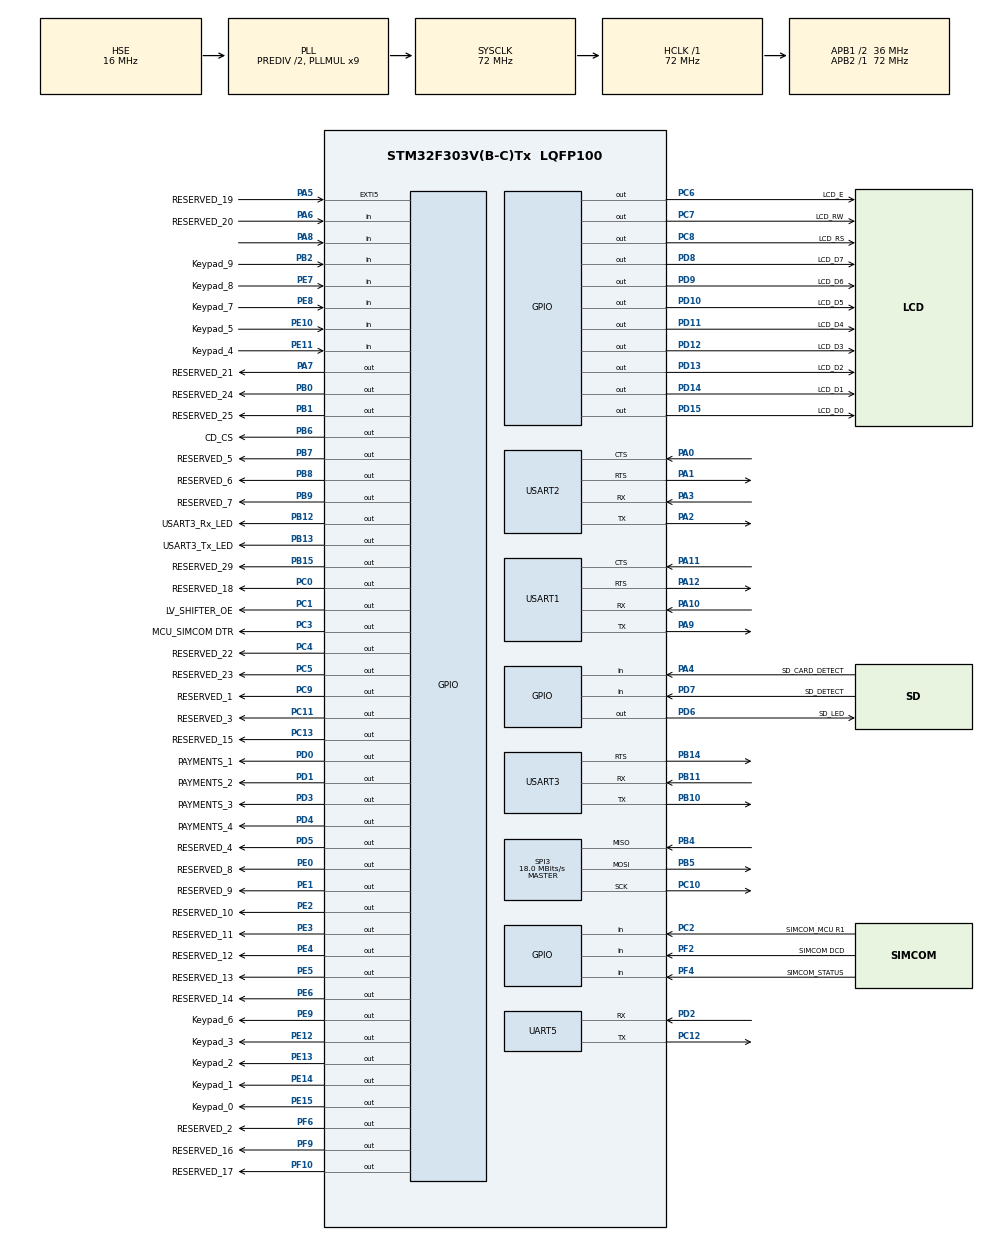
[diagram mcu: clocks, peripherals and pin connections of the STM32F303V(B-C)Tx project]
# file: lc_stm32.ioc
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FATFS._CODE_PAGE=1251
FREERTOS.Tasks01=defaultTask,0,128,StartDefaultTask,Default,NULL,Dynamic,NULL,NULL;keybScanTask,-3,128,KeybScanTask,Default,NULL,Dynamic,NULL,NULL
FREERTOS.configTOTAL_HEAP_SIZE=7000
FREERTOS.configUSE_TIMERS=1
Mcu.Family=STM32F3
Mcu.Name=STM32F303V(B-C)Tx
Mcu.Package=LQFP100
NVIC.PriorityGroup=NVIC_PRIORITYGROUP_4
NVIC.TIM1_BRK_TIM15_IRQn=true\:0\:0\:false\:false\:true\:false
NVIC.TimeBase=TIM1_BRK_TIM15_IRQn
NVIC.TimeBaseIP=TIM15
PA0.Mode=CTS_RTS
PA0.Signal=USART2_CTS
PA1.Mode=CTS_RTS
PA1.Signal=USART2_RTS
PA10.Mode=Asynchronous
PA10.Signal=USART1_RX
PA11.Mode=CTS_RTS
PA11.Signal=USART1_CTS
PA12.Mode=CTS_RTS
PA12.Signal=USART1_RTS
PA13.Mode=JTAG_4_pins
PA13.Signal=SYS_JTMS-SWDIO
PA14.Mode=JTAG_4_pins
PA14.Signal=SYS_JTCK-SWCLK
PA15.Mode=JTAG_4_pins
PA15.Signal=SYS_JTDI
PA2.Mode=Asynchronous
PA2.Signal=USART2_TX
PA3.Mode=Asynchronous
PA3.Signal=USART2_RX
PA4.GPIO_Label=SD_CARD_DETECT
PA4.Signal=GPIO_Input
PA5.GPIO_Label=RESERVED_19
PA5.GPIO_PuPd=GPIO_PULLDOWN
PA5.Signal=GPXTI5
PA6.GPIO_Label=RESERVED_20
PA6.GPIO_PuPd=GPIO_PULLDOWN
PA6.Signal=GPIO_Input
PA7.GPIO_Label=RESERVED_21
PA7.GPIO_PuPd=GPIO_PULLDOWN
PA7.Signal=GPIO_Output
PA8.Signal=GPIO_Input
PA9.Mode=Asynchronous
PA9.Signal=USART1_TX
PB0.GPIO_Label=RESERVED_24
PB0.GPIO_PuPd=GPIO_PULLDOWN
PB0.Signal=GPIO_Output
PB1.GPIO_Label=RESERVED_25
PB1.GPIO_PuPd=GPIO_PULLDOWN
PB1.Signal=GPIO_Output
PB10.Mode=Asynchronous
PB10.Signal=USART3_TX
PB11.Mode=Asynchronous
PB11.Signal=USART3_RX
PB12.GPIO_Label=USART3_Rx_LED
PB12.Signal=GPIO_Output
PB13.GPIO_Label=USART3_Tx_LED
PB13.Signal=GPIO_Output
PB14.Mode=RTS_Only
PB14.Signal=USART3_RTS
PB15.GPIO_Label=RESERVED_29
PB15.GPIO_PuPd=GPIO_PULLDOWN
PB15.Signal=GPIO_Output
PB2.GPIO_Label=Keypad_9
PB2.Signal=GPIO_Input
PB3.Mode=JTAG_4_pins
PB3.Signal=SYS_JTDO-TRACESWO
PB4.Mode=Full_Duplex_Master
PB4.Signal=SPI3_MISO
PB5.Mode=Full_Duplex_Master
PB5.Signal=SPI3_MOSI
PB6.GPIO_Label=CD_CS
PB6.Signal=GPIO_Output
PB7.GPIO_Label=RESERVED_5
PB7.GPIO_PuPd=GPIO_PULLDOWN
PB7.Signal=GPIO_Output
PB8.GPIO_Label=RESERVED_6
PB8.GPIO_PuPd=GPIO_PULLDOWN
PB8.Signal=GPIO_Output
PB9.GPIO_Label=RESERVED_7
PB9.GPIO_PuPd=GPIO_PULLDOWN
PB9.Signal=GPIO_Output
PC0.GPIO_Label=RESERVED_18
PC0.GPIO_PuPd=GPIO_PULLDOWN
PC0.Signal=GPIO_Output
PC1.GPIO_Label=LV_SHIFTER_OE
PC1.Signal=GPIO_Output
PC10.Mode=Full_Duplex_Master
PC10.Signal=SPI3_SCK
PC11.GPIO_Label=RESERVED_3
PC11.GPIO_PuPd=GPIO_PULLDOWN
PC11.Signal=GPIO_Output
PC12.Mode=Asynchronous
PC12.Signal=UART5_TX
PC13.GPIO_Label=RESERVED_15
PC13.GPIO_PuPd=GPIO_PULLDOWN
PC13.Signal=GPIO_Output
PC14-OSC32_IN.Mode=LSE-External-Oscillator
PC14-OSC32_IN.Signal=RCC_OSC32_IN
PC15-OSC32_OUT.Mode=LSE-External-Oscillator
PC15-OSC32_OUT.Signal=RCC_OSC32_OUT
PC2.GPIO_Label=SIMCOM_MCU R1
PC2.Signal=GPIO_Input
PC3.GPIO_Label=MCU_SIMCOM DTR
PC3.Signal=GPIO_Output
PC4.GPIO_Label=RESERVED_22
PC4.GPIO_PuPd=GPIO_PULLDOWN
PC4.Signal=GPIO_Output
PC5.GPIO_Label=RESERVED_23
PC5.GPIO_PuPd=GPIO_PULLDOWN
PC5.Signal=GPIO_Output
PC6.GPIO_Label=LCD_E
PC6.Signal=GPIO_Output
PC7.GPIO_Label=LCD_RW
PC7.Signal=GPIO_Output
PC8.GPIO_Label=LCD_RS
PC8.Signal=GPIO_Output
PC9.GPIO_Label=RESERVED_1
PC9.GPIO_PuPd=GPIO_PULLDOWN
PC9.Signal=GPIO_Output
PD0.GPIO_Label=PAYMENTS_1
PD0.Signal=GPIO_Output
PD1.GPIO_Label=PAYMENTS_2
PD1.Signal=GPIO_Output
PD10.GPIO_Label=LCD_D5
PD10.Signal=GPIO_Output
PD11.GPIO_Label=LCD_D4
PD11.Signal=GPIO_Output
PD12.GPIO_Label=LCD_D3
PD12.Signal=GPIO_Output
PD13.GPIO_Label=LCD_D2
PD13.Signal=GPIO_Output
PD14.GPIO_Label=LCD_D1
PD14.Signal=GPIO_Output
PD15.GPIO_Label=LCD_D0
PD15.Signal=GPIO_Output
PD2.Mode=Asynchronous
PD2.Signal=UART5_RX
PD3.GPIO_Label=PAYMENTS_3
PD3.Signal=GPIO_Output
PD4.GPIO_Label=PAYMENTS_4
PD4.Signal=GPIO_Output
PD5.GPIO_Label=RESERVED_4
PD5.GPIO_PuPd=GPIO_PULLDOWN
PD5.Signal=GPIO_Output
PD6.GPIO_Label=SD_LED
PD6.Signal=GPIO_Output
PD7.GPIO_Label=SD_DETECT
PD7.Signal=GPIO_Input
PD8.GPIO_Label=LCD_D7
PD8.Signal=GPIO_Output
PD9.GPIO_Label=LCD_D6
PD9.Signal=GPIO_Output
PE0.GPIO_Label=RESERVED_8
PE0.GPIO_PuPd=GPIO_PULLDOWN
PE0.Signal=GPIO_Output
PE1.GPIO_Label=RESERVED_9
PE1.GPIO_PuPd=GPIO_PULLDOWN
PE1.Signal=GPIO_Output
PE10.GPIO_Label=Keypad_5
PE10.Signal=GPIO_Input
PE11.GPIO_Label=Keypad_4
PE11.Signal=GPIO_Input
PE12.GPIO_Label=Keypad_3
PE12.Signal=GPIO_Output
PE13.GPIO_Label=Keypad_2
PE13.Signal=GPIO_Output
PE14.GPIO_Label=Keypad_1
PE14.Signal=GPIO_Output
PE15.GPIO_Label=Keypad_0
PE15.Signal=GPIO_Output
PE2.GPIO_Label=RESERVED_10
PE2.GPIO_PuPd=GPIO_PULLDOWN
PE2.Signal=GPIO_Output
PE3.GPIO_Label=RESERVED_11
PE3.GPIO_PuPd=GPIO_PULLDOWN
PE3.Signal=GPIO_Output
PE4.GPIO_Label=RESERVED_12
PE4.GPIO_PuPd=GPIO_PULLDOWN
PE4.Signal=GPIO_Output
PE5.GPIO_Label=RESERVED_13
PE5.GPIO_PuPd=GPIO_PULLDOWN
PE5.Signal=GPIO_Output
PE6.GPIO_Label=RESERVED_14
PE6.GPIO_PuPd=GPIO_PULLDOWN
PE6.Signal=GPIO_Output
PE7.GPIO_Label=Keypad_8
PE7.Signal=GPIO_Input
PE8.GPIO_Label=Keypad_7
PE8.Signal=GPIO_Input
PE9.GPIO_Label=Keypad_6
PE9.Signal=GPIO_Output
PF0-OSC_IN.Mode=HSE-External-Oscillator
PF0-OSC_IN.Signal=RCC_OSC_IN
PF1-OSC_OUT.Mode=HSE-External-Oscillator
PF1-OSC_OUT.Signal=RCC_OSC_OUT
PF10.GPIO_Label=RESERVED_17
PF10.GPIO_PuPd=GPIO_PULLDOWN
PF10.Signal=GPIO_Output
PF2.GPIO_Label=SIMCOM DCD
PF2.Signal=GPIO_Input
PF4.GPIO_Label=SIMCOM_STATUS
PF4.Signal=GPIO_Input
PF6.GPIO_Label=RESERVED_2
PF6.GPIO_PuPd=GPIO_PULLDOWN
PF6.Signal=GPIO_Output
PF9.GPIO_Label=RESERVED_16
PF9.GPIO_PuPd=GPIO_PULLDOWN
PF9.Signal=GPIO_Output
ProjectManager.HeapSize=0x200
ProjectManager.StackSize=0x400
ProjectManager.TargetToolchain=EWARM
RCC.AHBFreq_Value=72000000
RCC.APB1CLKDivider=RCC_HCLK_DIV2
RCC.APB1Freq_Value=36000000
RCC.APB1TimFreq_Value=72000000
RCC.APB2Freq_Value=72000000
RCC.APB2TimFreq_Value=72000000
RCC.CortexFreq_Value=72000000
RCC.HCLKFreq_Value=72000000
RCC.HSE_VALUE=16000000
RCC.HSIState=RCC_HSI_ON
RCC.HSI_VALUE=8000000
RCC.PLLMUL=RCC_PLL_MUL9
RCC.PLLSourceVirtual=RCC_PLLSOURCE_HSE
RCC.RCC_PLLsource_Clock_Source_FROM_HSE=RCC_HSE_PREDIV_DIV2
RCC.SYSCLKFreq_VALUE=72000000
RCC.SYSCLKSourceVirtual=RCC_SYSCLKSOURCE_PLLCLK
RCC.USBFreq_Value=72000000
SPI3.BaudRatePrescaler=SPI_BAUDRATEPRESCALER_2
SPI3.CalculateBaudRate=18.0 MBits/s
SPI3.Mode=SPI_MODE_MASTER
VP_FATFS_VS_Generic.Mode=User_defined
VP_FREERTOS_VS_ENABLE.Mode=Enabled
VP_IWDG_VS_IWDG.Mode=IWDG_Activate
VP_SYS_VS_tim15.Mode=TIM15
VP_TIM16_VS_ClockSourceINT.Mode=Enable_Timer
VP_TIM17_VS_ClockSourceINT.Mode=Enable_Timer
VP_TIM6_VS_ClockSourceINT.Mode=Enable_Timer
VP_TIM7_VS_ClockSourceINT.Mode=Enable_Timer
board=lc_stm32

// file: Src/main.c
/**
  ******************************************************************************
  * File Name          : main.c
  * Description        : Main program body
  ******************************************************************************
  *
  * Copyright (c) 2017 STMicroelectronics International N.V.
  * All rights reserved.
  *
  * Redistribution and use in source and binary forms, with or without
  * modification, are permitted, provided that the following conditions are met:
  *
  * 1. Redistribution of source code must retain the above copyright notice,
  *    this list of conditions and the following disclaimer.
  * 2. Redistributions in binary form must reproduce the above copyright notice,
  *    this list of conditions and the following disclaimer in the documentation
  *    and/or other materials provided with the distribution.
  * 3. Neither the name of STMicroelectronics nor the names of other
  *    contributors to this software may be used to endorse or promote products
  *    derived from this software without specific written permission.
  * 4. This software, including modifications and/or derivative works of this
  *    software, must execute solely and exclusively on microcontroller or
  *    microprocessor devices manufactured by or for STMicroelectronics.
  * 5. Redistribution and use of this software other than as permitted under
  *    this license is void and will automatically terminate your rights under
  *    this license.
  *
  * THIS SOFTWARE IS PROVIDED BY STMICROELECTRONICS AND CONTRIBUTORS "AS IS"
  * AND ANY EXPRESS, IMPLIED OR STATUTORY WARRANTIES, INCLUDING, BUT NOT
  * LIMITED TO, THE IMPLIED WARRANTIES OF MERCHANTABILITY, FITNESS FOR A
  * PARTICULAR PURPOSE AND NON-INFRINGEMENT OF THIRD PARTY INTELLECTUAL PROPERTY
  * RIGHTS ARE DISCLAIMED TO THE FULLEST EXTENT PERMITTED BY LAW. IN NO EVENT
  * SHALL STMICROELECTRONICS OR CONTRIBUTORS BE LIABLE FOR ANY DIRECT, INDIRECT,
  * INCIDENTAL, SPECIAL, EXEMPLARY, OR CONSEQUENTIAL DAMAGES (INCLUDING, BUT NOT
  * LIMITED TO, PROCUREMENT OF SUBSTITUTE GOODS OR SERVICES; LOSS OF USE, DATA,
  * OR PROFITS; OR BUSINESS INTERRUPTION) HOWEVER CAUSED AND ON ANY THEORY OF
  * LIABILITY, WHETHER IN CONTRACT, STRICT LIABILITY, OR TORT (INCLUDING
  * NEGLIGENCE OR OTHERWISE) ARISING IN ANY WAY OUT OF THE USE OF THIS SOFTWARE,
  * EVEN IF ADVISED OF THE POSSIBILITY OF SUCH DAMAGE.
  *
  ******************************************************************************
  */
#include "main.h"
#include "stm32f3xx_hal.h"
#include "cmsis_os.h"
#include "fatfs.h"
#include "iwdg.h"
#include "spi.h"
#include "tim.h"
#include "usart.h"
#include "gpio.h"

/* USER CODE BEGIN Includes */
#include "timer16.h"
#include "timer17.h"
#include "SIMCOM_drive.hpp"
/* USER CODE END Includes */

/* USER CODE BEGIN PV */
/* Private variables ---------------------------------------------------------*/

/* USER CODE END PV */

void SystemClock_Config(void);
void Error_Handler(void);
void MX_FREERTOS_Init(void);

/* USER CODE BEGIN PFP */
/* Private function prototypes -----------------------------------------------*/

/* USER CODE END PFP */

int main(void)
{
  uint8_t TestString[]={0xAA,0xAA,0xAA,0xAA,0xAA,0xAA,0xAA,0xAA,0xAA,0xAA,0xAA,0xAA};

  /* MCU Configuration----------------------------------------------------------*/

  /* Reset of all peripherals, Initializes the Flash interface and the Systick. */
  HAL_Init();

  /* Configure the system clock */
  SystemClock_Config();

  /* Initialize all configured peripherals */
  MX_GPIO_Init();
  MX_SPI3_Init();
  MX_UART5_Init();
  MX_USART1_UART_Init();
  MX_USART2_UART_Init();
  MX_USART3_UART_Init();
//  MX_IWDG_Init();
  MX_TIM6_Init();
  MX_TIM7_Init();
  MX_TIM16_Init();
  MX_TIM17_Init();

  /* Call init function for freertos objects (in freertos.c) */
  MX_FREERTOS_Init();

  TIM16_Init();
  TIM17_Init();
  SIM800_init();
//  while(1){
//  HAL_UART_Transmit(&huart2, TestString, sizeof(TestString) ,100);
//  }
  /* Start scheduler */
  osKernelStart();

  /* We should never get here as control is now taken by the scheduler */

  /* Infinite loop */
  while (1)
  {

  }

}

/** System Clock Configuration
*/
void SystemClock_Config(void)
{

  RCC_OscInitTypeDef RCC_OscInitStruct;
  RCC_ClkInitTypeDef RCC_ClkInitStruct;
  RCC_PeriphCLKInitTypeDef PeriphClkInit;

    /**Initializes the CPU, AHB and APB busses clocks
    */
  RCC_OscInitStruct.OscillatorType = RCC_OSCILLATORTYPE_LSI|RCC_OSCILLATORTYPE_HSE;
  RCC_OscInitStruct.HSEState = RCC_HSE_ON;
  RCC_OscInitStruct.HSEPredivValue = RCC_HSE_PREDIV_DIV2;
  RCC_OscInitStruct.HSIState = RCC_HSI_ON;
  RCC_OscInitStruct.LSIState = RCC_LSI_ON;
  RCC_OscInitStruct.PLL.PLLState = RCC_PLL_ON;
  RCC_OscInitStruct.PLL.PLLSource = RCC_PLLSOURCE_HSE;
  RCC_OscInitStruct.PLL.PLLMUL = RCC_PLL_MUL9;
  if (HAL_RCC_OscConfig(&RCC_OscInitStruct) != HAL_OK)
  {
    Error_Handler();
  }

    /**Initializes the CPU, AHB and APB busses clocks
    */
  RCC_ClkInitStruct.ClockType = RCC_CLOCKTYPE_HCLK|RCC_CLOCKTYPE_SYSCLK
                              |RCC_CLOCKTYPE_PCLK1|RCC_CLOCKTYPE_PCLK2;
  RCC_ClkInitStruct.SYSCLKSource = RCC_SYSCLKSOURCE_PLLCLK;
  RCC_ClkInitStruct.AHBCLKDivider = RCC_SYSCLK_DIV1;
  RCC_ClkInitStruct.APB1CLKDivider = RCC_HCLK_DIV2;
  RCC_ClkInitStruct.APB2CLKDivider = RCC_HCLK_DIV1;

  if (HAL_RCC_ClockConfig(&RCC_ClkInitStruct, FLASH_LATENCY_2) != HAL_OK)
  {
    Error_Handler();
  }

  PeriphClkInit.PeriphClockSelection = RCC_PERIPHCLK_USART1|RCC_PERIPHCLK_USART2
                              |RCC_PERIPHCLK_USART3|RCC_PERIPHCLK_UART5;
  PeriphClkInit.Usart1ClockSelection = RCC_USART1CLKSOURCE_PCLK2;
  PeriphClkInit.Usart2ClockSelection = RCC_USART2CLKSOURCE_PCLK1;
  PeriphClkInit.Usart3ClockSelection = RCC_USART3CLKSOURCE_PCLK1;
  PeriphClkInit.Uart5ClockSelection = RCC_UART5CLKSOURCE_PCLK1;
  if (HAL_RCCEx_PeriphCLKConfig(&PeriphClkInit) != HAL_OK)
  {
    Error_Handler();
  }

    /**Configure the Systick interrupt time
    */
  HAL_SYSTICK_Config(HAL_RCC_GetHCLKFreq()/1000);

    /**Configure the Systick
    */
  HAL_SYSTICK_CLKSourceConfig(SYSTICK_CLKSOURCE_HCLK);

  /* SysTick_IRQn interrupt configuration */
  HAL_NVIC_SetPriority(SysTick_IRQn, 15, 0);
}

void HAL_TIM_PeriodElapsedCallback(TIM_HandleTypeDef *htim)
{
  if (htim->Instance == TIM15) {
    HAL_IncTick();
  }
}

void Error_Handler(void)
{
  while(1)
  {
  }
}

/************************ (C) COPYRIGHT STMicroelectronics *****END OF FILE****/

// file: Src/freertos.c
/**
  ******************************************************************************
  * File Name          : freertos.c
  * Description        : Code for freertos applications
  ******************************************************************************
  *
  * Copyright (c) 2017 STMicroelectronics International N.V.
  * All rights reserved.
  *
  * Redistribution and use in source and binary forms, with or without
  * modification, are permitted, provided that the following conditions are met:
  *
  * 1. Redistribution of source code must retain the above copyright notice,
  *    this list of conditions and the following disclaimer.
  * 2. Redistributions in binary form must reproduce the above copyright notice,
  *    this list of conditions and the following disclaimer in the documentation
  *    and/or other materials provided with the distribution.
  * 3. Neither the name of STMicroelectronics nor the names of other
  *    contributors to this software may be used to endorse or promote products
  *    derived from this software without specific written permission.
  * 4. This software, including modifications and/or derivative works of this
  *    software, must execute solely and exclusively on microcontroller or
  *    microprocessor devices manufactured by or for STMicroelectronics.
  * 5. Redistribution and use of this software other than as permitted under
  *    this license is void and will automatically terminate your rights under
  *    this license.
  *
  * THIS SOFTWARE IS PROVIDED BY STMICROELECTRONICS AND CONTRIBUTORS "AS IS"
  * AND ANY EXPRESS, IMPLIED OR STATUTORY WARRANTIES, INCLUDING, BUT NOT
  * LIMITED TO, THE IMPLIED WARRANTIES OF MERCHANTABILITY, FITNESS FOR A
  * PARTICULAR PURPOSE AND NON-INFRINGEMENT OF THIRD PARTY INTELLECTUAL PROPERTY
  * RIGHTS ARE DISCLAIMED TO THE FULLEST EXTENT PERMITTED BY LAW. IN NO EVENT
  * SHALL STMICROELECTRONICS OR CONTRIBUTORS BE LIABLE FOR ANY DIRECT, INDIRECT,
  * INCIDENTAL, SPECIAL, EXEMPLARY, OR CONSEQUENTIAL DAMAGES (INCLUDING, BUT NOT
  * LIMITED TO, PROCUREMENT OF SUBSTITUTE GOODS OR SERVICES; LOSS OF USE, DATA,
  * OR PROFITS; OR BUSINESS INTERRUPTION) HOWEVER CAUSED AND ON ANY THEORY OF
  * LIABILITY, WHETHER IN CONTRACT, STRICT LIABILITY, OR TORT (INCLUDING
  * NEGLIGENCE OR OTHERWISE) ARISING IN ANY WAY OUT OF THE USE OF THIS SOFTWARE,
  * EVEN IF ADVISED OF THE POSSIBILITY OF SUCH DAMAGE.
  *
  ******************************************************************************
  */

#include "FreeRTOS.h"
#include "task.h"
#include "cmsis_os.h"
#include "iwdg.h"
#include "timer16.h"
#include "SIMCOM_drive.hpp"

/* USER CODE BEGIN Includes */
#include "sdcard.hpp"
/* USER CODE END Includes */

osThreadId defaultTaskHandle;

/* USER CODE BEGIN Variables */
osThreadId keybScanTaskHandle;
osThreadId SIM800_queueTaskHandle;
/* USER CODE END Variables */

void StartDefaultTask(void const * argument);
void KeybScanTask(void const * argument);
void _SIM800_queueTask(void const * argument);

extern void MX_FATFS_Init(void);
void MX_FREERTOS_Init(void); /* (MISRA C 2004 rule 8.1) */

/* Hook prototypes */

/* Init FreeRTOS */

void MX_FREERTOS_Init(void) {

  /* Create the thread(s) */
  /* definition and creation of defaultTask */
  osThreadDef(defaultTask, StartDefaultTask, osPriorityNormal, 0, 128);
  defaultTaskHandle = osThreadCreate(osThread(defaultTask), NULL);

  /* USER CODE BEGIN RTOS_THREADS */
  /* add threads, ... */
  /* definition and creation of keybScanTask */
  osThreadDef(keybScanTask, KeybScanTask, osPriorityIdle, 0, 128);
  keybScanTaskHandle = osThreadCreate(osThread(keybScanTask), NULL);

  osThreadDef(SIM800_queueTask, _SIM800_queueTask, osPriorityBelowNormal, 0, 528);
  SIM800_queueTaskHandle = osThreadCreate(osThread(SIM800_queueTask), NULL);
  /* USER CODE END RTOS_THREADS */

}

/* StartDefaultTask function */
void StartDefaultTask(void const * argument)
{
  /* init code for FATFS */
  MX_FATFS_Init();

  for(;;)
  {
    osDelay(1);
  }
}

/* KeybScanTask function */
void KeybScanTask(void const * argument)
{
  /* USER CODE BEGIN KeybScanTask */
  /* Infinite loop */
  for(;;)
  {

    TIM16_Start();
    osDelay(500);
    TIM16_Stop();
    osDelay(500);
  }
  /* USER CODE END KeybScanTask */
}

void _SIM800_queueTask(void const * argument){
  for(;;)
  {
  SIM800_queue_handler();
  }
}

/************************ (C) COPYRIGHT STMicroelectronics *****END OF FILE****/
